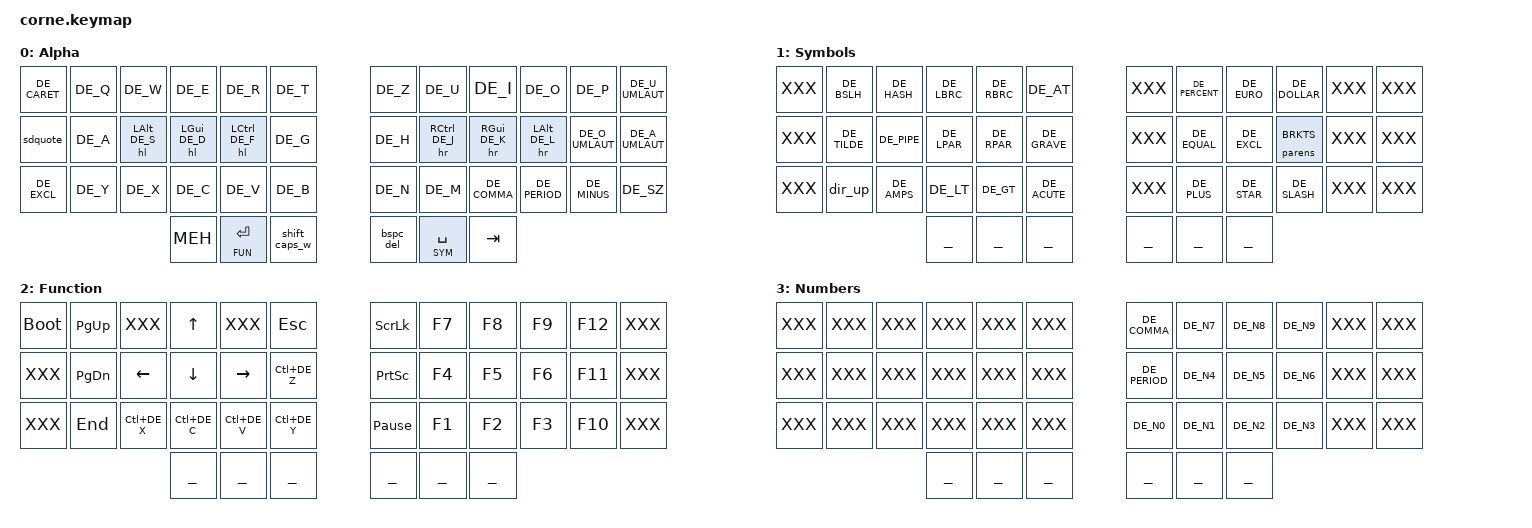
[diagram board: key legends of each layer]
#include <behaviors.dtsi>
#include <dt-bindings/zmk/keys.h>
#include <dt-bindings/zmk/bt.h>
#include <dt-bindings/zmk/ext_power.h>

#include "zmk-helpers/helper.h"

#include "./helpers.h"
#include "./keys_de.h"

/* Layers */

#define ALPHA 0
#define SYM 1
#define FUN 2
#define NUM 3

/* Home Row Mods */

// Left-hand side home row mod. The prefix `hl` somewhat stands for "home row mod on the left side".
MAKE_HRM(hl, &kp, &kp, RIGHT_SIDE_KEYS THUMB_KEYS)

// Right-hand side home row mod. The prefix `hr` somewhat stands for "home row mod on the right side".
MAKE_HRM(hr, &kp, &kp, LEFT_SIDE_KEYS THUMB_KEYS)

/* Misc */

ZMK_COMBO(tog_num, \
    &tog NUM, \
    RB1 RB2, \
    ALL, \
    COMBO_TERM, \
    HRM_TAPPING_TERM \
)

ZMK_COMBO(cancel, \
    &to ALPHA, \
    RM1 RM2, \
    ALL, \
    COMBO_TERM, \
    HRM_TAPPING_TERM \
)

ZMK_MOD_MORPH(sdquote, \
    mods = <(MOD_LSFT|MOD_RSFT)>; \
    keep-mods = <0>; \
    bindings = \
        <&kp DE_SQT>, \
        <&kp DE_DQT>; \
)

ZMK_MOD_MORPH(bspc_del, \
    mods = <(MOD_LSFT|MOD_RSFT)>; \
    keep-mods = <0>; \
    bindings = \
        <&kp BSPC>, \
        <&kp DEL>; \
)

ZMK_BEHAVIOR(shift_caps_w, tap_dance,
    tapping-term-ms = <200>;
    bindings = <&sk LSHFT>, <&caps_word>;
)

ZMK_MACRO_TWO_PARAM(parens, bindings =
    <&macro_param_1to1>,
    <&kp MACRO_PLACEHOLDER &macro_param_2to1>,
    <&kp MACRO_PLACEHOLDER &kp LEFT>;
)

ZMK_MACRO(dir_up, bindings =
    <&kp DE_DOT &kp DE_DOT &kp DE_SLASH>;
)

/* Layers */

ZMK_LAYER(Alpha,
//╭────────────────┬────────────────┬────────────────┬────────────────┬────────────────┬────────────────╮        ╭────────────────┬────────────────┬────────────────┬────────────────┬────────────────┬────────────────╮
    &kp DE_CARET     &kp DE_Q         &kp DE_W         &kp DE_E         &kp DE_R         &kp DE_T                  &kp DE_Z         &kp DE_U         &kp DE_I         &kp DE_O         &kp DE_P         &kp DE_U_UMLAUT
//├────────────────┼────────────────┼────────────────┼────────────────┼────────────────┼────────────────┤        ├────────────────┼────────────────┼────────────────┼────────────────┼────────────────┼────────────────┤
    &sdquote         &kp DE_A         &hl LALT DE_S    &hl LGUI DE_D    &hl LCTRL DE_F   &kp DE_G                  &kp DE_H         &hr RCTRL DE_J   &hr RGUI DE_K    &hr LALT DE_L    &kp DE_O_UMLAUT  &kp DE_A_UMLAUT
//├────────────────┼────────────────┼────────────────┼────────────────┼────────────────┼────────────────┤        ├────────────────┼────────────────┼────────────────┼────────────────┼────────────────┼────────────────┤
    &kp DE_EXCL      &kp DE_Y         &kp DE_X         &kp DE_C         &kp DE_V         &kp DE_B                  &kp DE_N         &kp DE_M         &kp DE_COMMA     &kp DE_PERIOD    &kp DE_MINUS     &kp DE_SZ
//╰────────────────┴────────────────┴────────────────┼────────────────┼────────────────┼────────────────┤        ├────────────────┼────────────────┼────────────────┼────────────────┴────────────────┴────────────────╯
                                                       &kp MEH          &lt FUN ENTER    &shift_caps_w             &bspc_del        &lt SYM SPACE    &kp TAB
//                                                   ╰────────────────┴────────────────┴────────────────╯        ╰────────────────┴────────────────┴────────────────╯
)

ZMK_LAYER(Symbols,
//╭────────────────┬────────────────┬────────────────┬────────────────┬────────────────┬────────────────╮        ╭────────────────┬────────────────┬────────────────┬────────────────┬────────────────┬────────────────╮
    XXX              &kp DE_BSLH      &kp DE_HASH      &kp DE_LBRC      &kp DE_RBRC      &kp DE_AT                 XXX              &kp DE_PERCENT   &kp DE_EURO      &kp DE_DOLLAR    XXX              XXX
//├────────────────┼────────────────┼────────────────┼────────────────┼────────────────┼────────────────┤        ├────────────────┼────────────────┼────────────────┼────────────────┼────────────────┼────────────────┤
    XXX              &kp DE_TILDE     &kp DE_PIPE      &kp DE_LPAR      &kp DE_RPAR      &kp DE_GRAVE              XXX              &kp DE_EQUAL     &kp DE_EXCL      &parens BRKTS    XXX              XXX
//├────────────────┼────────────────┼────────────────┼────────────────┼────────────────┼────────────────┤        ├────────────────┼────────────────┼────────────────┼────────────────┼────────────────┼────────────────┤
    XXX              &dir_up           &kp DE_AMPS      &kp DE_LT        &kp DE_GT        &kp DE_ACUTE              XXX              &kp DE_PLUS      &kp DE_STAR      &kp DE_SLASH     XXX              XXX
//╰────────────────┴────────────────┴────────────────┼────────────────┼────────────────┼────────────────┤        ├────────────────┼────────────────┼────────────────┼────────────────┴────────────────┴────────────────╯
                                                       ___              ___              ___                       ___              ___              ___
//                                                   ╰────────────────┴────────────────┴────────────────╯        ╰────────────────┴────────────────┴────────────────╯
)

ZMK_LAYER(Function,
//╭────────────────┬────────────────┬────────────────┬────────────────┬────────────────┬────────────────╮        ╭────────────────┬────────────────┬────────────────┬────────────────┬────────────────┬────────────────╮
    &bootloader      &kp PAGE_UP      XXX              &kp UP           XXX              &kp ESC                   &kp SCROLLLOCK   &kp F7           &kp F8           &kp F9           &kp F12          XXX
//├────────────────┼────────────────┼────────────────┼────────────────┼────────────────┼────────────────┤        ├────────────────┼────────────────┼────────────────┼────────────────┼────────────────┼────────────────┤
    XXX              &kp PAGE_DOWN    &kp LEFT         &kp DOWN         &kp RIGHT        &kp LC(DE_Z)              &kp PSCRN        &kp F4           &kp F5           &kp F6           &kp F11          XXX
//├────────────────┼────────────────┼────────────────┼────────────────┼────────────────┼────────────────┤        ├────────────────┼────────────────┼────────────────┼────────────────┼────────────────┼────────────────┤
    XXX              &kp END          &kp LC(DE_X)     &kp LC(DE_C)     &kp LC(DE_V)     &kp LC(DE_Y)              &kp PAUSE_BREAK  &kp F1           &kp F2           &kp F3           &kp F10          XXX
//╰────────────────┴────────────────┴────────────────┼────────────────┼────────────────┼────────────────┤        ├────────────────┼────────────────┼────────────────┼────────────────┴────────────────┴────────────────╯
                                                       ___              ___              ___                       ___              ___              ___
//                                                   ╰────────────────┴────────────────┴────────────────╯        ╰────────────────┴────────────────┴────────────────╯
)

ZMK_LAYER(Numbers,
//╭────────────────┬────────────────┬────────────────┬────────────────┬────────────────┬────────────────╮        ╭────────────────┬────────────────┬────────────────┬────────────────┬────────────────┬────────────────╮
    XXX              XXX              XXX              XXX              XXX              XXX                       &kp DE_COMMA     &kp DE_N7        &kp DE_N8        &kp DE_N9        XXX              XXX
//├────────────────┼────────────────┼────────────────┼────────────────┼────────────────┼────────────────┤        ├────────────────┼────────────────┼────────────────┼────────────────┼────────────────┼────────────────┤
    XXX              XXX              XXX              XXX              XXX              XXX                       &kp DE_PERIOD    &kp DE_N4        &kp DE_N5        &kp DE_N6        XXX              XXX
//├────────────────┼────────────────┼────────────────┼────────────────┼────────────────┼────────────────┤        ├────────────────┼────────────────┼────────────────┼────────────────┼────────────────┼────────────────┤
    XXX              XXX              XXX              XXX              XXX              XXX                       &kp DE_N0        &kp DE_N1        &kp DE_N2        &kp DE_N3        XXX              XXX
//╰────────────────┴────────────────┴────────────────┼────────────────┼────────────────┼────────────────┤        ├────────────────┼────────────────┼────────────────┼────────────────┴────────────────┴────────────────╯
                                                       ___              ___              ___                       ___              ___              ___
//                                                   ╰────────────────┴────────────────┴────────────────╯        ╰────────────────┴────────────────┴────────────────╯
)
